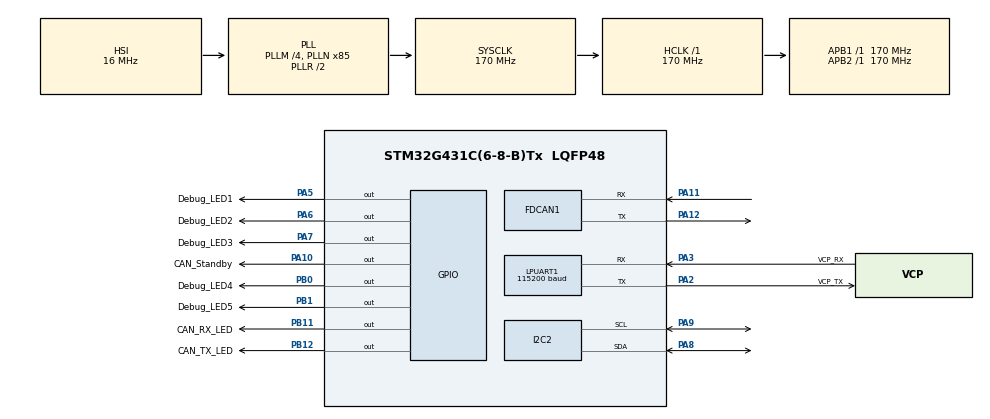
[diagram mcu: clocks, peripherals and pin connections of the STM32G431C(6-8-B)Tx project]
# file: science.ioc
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Dma.LPUART1_TX.0.Direction=DMA_MEMORY_TO_PERIPH
Dma.LPUART1_TX.0.EventEnable=DISABLE
Dma.LPUART1_TX.0.Instance=DMA2_Channel1
Dma.LPUART1_TX.0.MemDataAlignment=DMA_MDATAALIGN_BYTE
Dma.LPUART1_TX.0.MemInc=DMA_MINC_ENABLE
Dma.LPUART1_TX.0.Mode=DMA_NORMAL
Dma.LPUART1_TX.0.PeriphDataAlignment=DMA_PDATAALIGN_BYTE
Dma.LPUART1_TX.0.PeriphInc=DMA_PINC_DISABLE
Dma.LPUART1_TX.0.Polarity=HAL_DMAMUX_REQ_GEN_RISING
Dma.LPUART1_TX.0.Priority=DMA_PRIORITY_LOW
Dma.LPUART1_TX.0.RequestNumber=1
Dma.LPUART1_TX.0.SignalID=NONE
Dma.LPUART1_TX.0.SyncEnable=DISABLE
Dma.LPUART1_TX.0.SyncPolarity=HAL_DMAMUX_SYNC_NO_EVENT
Dma.LPUART1_TX.0.SyncRequestNumber=1
Dma.LPUART1_TX.0.SyncSignalID=NONE
Dma.Request0=LPUART1_TX
FDCAN1.AutoRetransmission=ENABLE
FDCAN1.CalculateBaudRateNominal=999999
FDCAN1.CalculateTimeBitNominal=1000
FDCAN1.CalculateTimeQuantumNominal=11.764705882352942
FDCAN1.ClockDivider=FDCAN_CLOCK_DIV2
FDCAN1.DataSyncJumpWidth=5
FDCAN1.DataTimeSeg1=11
FDCAN1.DataTimeSeg2=5
FDCAN1.ExtFiltersNbr=3
FDCAN1.FrameFormat=FDCAN_FRAME_FD_BRS
FDCAN1.NominalPrescaler=1
FDCAN1.NominalSyncJumpWidth=16
FDCAN1.NominalTimeSeg1=56
FDCAN1.NominalTimeSeg2=28
I2C2.Timing=0x40B285C2
LPUART1.BaudRate=115200
LPUART1.FIFOMode=UART_FIFOMODE_ENABLE
Mcu.Family=STM32G4
Mcu.Name=STM32G431C(6-8-B)Tx
Mcu.Package=LQFP48
NVIC.DMA2_Channel1_IRQn=true\:6\:0\:true\:false\:true\:false\:true\:true
NVIC.FDCAN1_IT0_IRQn=true\:0\:0\:false\:false\:true\:true\:true\:true
NVIC.FDCAN1_IT1_IRQn=true\:0\:0\:false\:false\:true\:true\:true\:true
NVIC.LPUART1_IRQn=true\:0\:0\:false\:false\:true\:true\:true\:true
NVIC.PriorityGroup=NVIC_PRIORITYGROUP_3
NVIC.TIM1_BRK_TIM15_IRQn=true\:0\:0\:true\:false\:true\:true\:true\:true
NVIC.TIM1_UP_TIM16_IRQn=true\:0\:0\:true\:false\:true\:true\:true\:true
NVIC.TIM2_IRQn=true\:3\:0\:true\:false\:true\:true\:true\:true
NVIC.TIM3_IRQn=true\:2\:0\:true\:false\:true\:true\:true\:true
NVIC.TIM6_DAC_IRQn=true\:4\:0\:true\:false\:true\:true\:true\:true
NVIC.TIM7_IRQn=true\:0\:0\:true\:false\:true\:true\:true\:true
PA10.GPIO_Label=CAN_Standby
PA10.Signal=GPIO_Output
PA11.Mode=FDCAN_Activate
PA11.Signal=FDCAN1_RX
PA12.Mode=FDCAN_Activate
PA12.Signal=FDCAN1_TX
PA13.GPIO_Label=SWDIO
PA13.Mode=Trace_Asynchronous_SW
PA13.Signal=SYS_JTMS-SWDIO
PA14.GPIO_Label=SWCLK
PA14.Mode=Trace_Asynchronous_SW
PA14.Signal=SYS_JTCK-SWCLK
PA2.GPIO_Label=VCP_TX
PA2.Mode=Asynchronous
PA2.Signal=LPUART1_TX
PA3.GPIO_Label=VCP_RX
PA3.Mode=Asynchronous
PA3.Signal=LPUART1_RX
PA5.GPIO_Label=Debug_LED1
PA5.Signal=GPIO_Output
PA6.GPIO_Label=Debug_LED2
PA6.Signal=GPIO_Output
PA7.GPIO_Label=Debug_LED3
PA7.Signal=GPIO_Output
PA8.Mode=I2C
PA8.Signal=I2C2_SDA
PA9.Mode=I2C
PA9.Signal=I2C2_SCL
PB0.GPIO_Label=Debug_LED4
PB0.Signal=GPIO_Output
PB1.GPIO_Label=Debug_LED5
PB1.Signal=GPIO_Output
PB11.GPIO_Label=CAN_RX_LED
PB11.Signal=GPIO_Output
PB12.GPIO_Label=CAN_TX_LED
PB12.Signal=GPIO_Output
PB3.GPIO_Label=SWO
PB3.Mode=Trace_Asynchronous_SW
PB3.Signal=SYS_JTDO-SWO
ProjectManager.HeapSize=0x200
ProjectManager.StackSize=0x400
ProjectManager.TargetToolchain=CMake
RCC.ADC12Freq_Value=170000000
RCC.AHBFreq_Value=170000000
RCC.APB1Freq_Value=170000000
RCC.APB1TimFreq_Value=170000000
RCC.APB2Freq_Value=170000000
RCC.APB2TimFreq_Value=170000000
RCC.CortexFreq_Value=170000000
RCC.EXTERNAL_CLOCK_VALUE=12288000
RCC.HCLKFreq_Value=170000000
RCC.HSE_VALUE=8000000
RCC.HSI48_VALUE=48000000
RCC.HSI_VALUE=16000000
RCC.LSE_VALUE=32768
RCC.PLLM=RCC_PLLM_DIV4
RCC.PLLN=85
RCC.SYSCLKFreq_VALUE=170000000
RCC.SYSCLKSource=RCC_SYSCLKSOURCE_PLLCLK
RCC.USBFreq_Value=170000000
RCC.VCOOutputFreq_Value=340000000
TIM15.PeriodNoDither=999
TIM15.Prescaler=16999
TIM16.PeriodNoDither=9999
TIM16.Prescaler=16999
TIM2.PeriodNoDither=3999
TIM2.Prescaler=16999
TIM3.PeriodNoDither=999
TIM3.Prescaler=16999
TIM6.PeriodNoDither=4999
TIM6.Prescaler=16999
TIM7.PeriodNoDither=499
TIM7.Prescaler=16999
VP_SYS_VS_DBSignals.Mode=DisableDeadBatterySignals
VP_TIM15_VS_ClockSourceINT.Mode=Internal
VP_TIM16_VS_ClockSourceINT.Mode=Enable_Timer
VP_TIM2_VS_ClockSourceINT.Mode=Internal
VP_TIM3_VS_ClockSourceINT.Mode=Internal
VP_TIM6_VS_ClockSourceINT.Mode=Enable_Timer
VP_TIM7_VS_ClockSourceINT.Mode=Enable_Timer
board=custom

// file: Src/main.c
/* USER CODE BEGIN Header */
/**
  ******************************************************************************
  * @file           : main.c
  * @brief          : Main program body
  ******************************************************************************
  * @attention
  *
  * Copyright (c) 2026 STMicroelectronics.
  * All rights reserved.
  *
  * This software is licensed under terms that can be found in the LICENSE file
  * in the root directory of this software component.
  * If no LICENSE file comes with this software, it is provided AS-IS.
  *
  ******************************************************************************
  */
/* USER CODE END Header */
#include "main.h"

FDCAN_HandleTypeDef hfdcan1;

I2C_HandleTypeDef hi2c2;

UART_HandleTypeDef hlpuart1;
DMA_HandleTypeDef hdma_lpuart1_tx;

TIM_HandleTypeDef htim2;
TIM_HandleTypeDef htim3;
TIM_HandleTypeDef htim6;
TIM_HandleTypeDef htim7;
TIM_HandleTypeDef htim15;
TIM_HandleTypeDef htim16;

void SystemClock_Config(void);
static void MX_GPIO_Init(void);
static void MX_DMA_Init(void);
static void MX_FDCAN1_Init(void);
static void MX_TIM2_Init(void);
static void MX_TIM3_Init(void);
static void MX_LPUART1_UART_Init(void);
static void MX_TIM6_Init(void);
static void MX_TIM15_Init(void);
static void MX_TIM16_Init(void);
static void MX_TIM7_Init(void);
static void MX_I2C2_Init(void);

int main(void)
{

  /* MCU Configuration--------------------------------------------------------*/

  /* Reset of all peripherals, Initializes the Flash interface and the Systick. */
  HAL_Init();

  /* Configure the system clock */
  SystemClock_Config();

  /* Initialize all configured peripherals */
  MX_GPIO_Init();
  MX_DMA_Init();
  MX_FDCAN1_Init();
  MX_TIM2_Init();
  MX_TIM3_Init();
  MX_LPUART1_UART_Init();
  MX_TIM6_Init();
  MX_TIM15_Init();
  MX_TIM16_Init();
  MX_TIM7_Init();
  MX_I2C2_Init();

  /* Infinite loop */
  /* USER CODE BEGIN WHILE */
  PostInit();
  while (1)
  {
    /* USER CODE END WHILE */

  }
}

void SystemClock_Config(void)
{
  RCC_OscInitTypeDef RCC_OscInitStruct = {0};
  RCC_ClkInitTypeDef RCC_ClkInitStruct = {0};

  /** Configure the main internal regulator output voltage
  */
  HAL_PWREx_ControlVoltageScaling(PWR_REGULATOR_VOLTAGE_SCALE1_BOOST);

  /** Initializes the RCC Oscillators according to the specified parameters
  * in the RCC_OscInitTypeDef structure.
  */
  RCC_OscInitStruct.OscillatorType = RCC_OSCILLATORTYPE_HSI;
  RCC_OscInitStruct.HSIState = RCC_HSI_ON;
  RCC_OscInitStruct.HSICalibrationValue = RCC_HSICALIBRATION_DEFAULT;
  RCC_OscInitStruct.PLL.PLLState = RCC_PLL_ON;
  RCC_OscInitStruct.PLL.PLLSource = RCC_PLLSOURCE_HSI;
  RCC_OscInitStruct.PLL.PLLM = RCC_PLLM_DIV4;
  RCC_OscInitStruct.PLL.PLLN = 85;
  RCC_OscInitStruct.PLL.PLLP = RCC_PLLP_DIV2;
  RCC_OscInitStruct.PLL.PLLQ = RCC_PLLQ_DIV2;
  RCC_OscInitStruct.PLL.PLLR = RCC_PLLR_DIV2;
  if (HAL_RCC_OscConfig(&RCC_OscInitStruct) != HAL_OK)
  {
    Error_Handler();
  }

  /** Initializes the CPU, AHB and APB buses clocks
  */
  RCC_ClkInitStruct.ClockType = RCC_CLOCKTYPE_HCLK|RCC_CLOCKTYPE_SYSCLK
                              |RCC_CLOCKTYPE_PCLK1|RCC_CLOCKTYPE_PCLK2;
  RCC_ClkInitStruct.SYSCLKSource = RCC_SYSCLKSOURCE_PLLCLK;
  RCC_ClkInitStruct.AHBCLKDivider = RCC_SYSCLK_DIV1;
  RCC_ClkInitStruct.APB1CLKDivider = RCC_HCLK_DIV1;
  RCC_ClkInitStruct.APB2CLKDivider = RCC_HCLK_DIV1;

  if (HAL_RCC_ClockConfig(&RCC_ClkInitStruct, FLASH_LATENCY_4) != HAL_OK)
  {
    Error_Handler();
  }
}

static void MX_FDCAN1_Init(void)
{

  hfdcan1.Instance = FDCAN1;
  hfdcan1.Init.ClockDivider = FDCAN_CLOCK_DIV2;
  hfdcan1.Init.FrameFormat = FDCAN_FRAME_FD_BRS;
  hfdcan1.Init.Mode = FDCAN_MODE_NORMAL;
  hfdcan1.Init.AutoRetransmission = ENABLE;
  hfdcan1.Init.TransmitPause = DISABLE;
  hfdcan1.Init.ProtocolException = DISABLE;
  hfdcan1.Init.NominalPrescaler = 1;
  hfdcan1.Init.NominalSyncJumpWidth = 16;
  hfdcan1.Init.NominalTimeSeg1 = 56;
  hfdcan1.Init.NominalTimeSeg2 = 28;
  hfdcan1.Init.DataPrescaler = 1;
  hfdcan1.Init.DataSyncJumpWidth = 5;
  hfdcan1.Init.DataTimeSeg1 = 11;
  hfdcan1.Init.DataTimeSeg2 = 5;
  hfdcan1.Init.StdFiltersNbr = 0;
  hfdcan1.Init.ExtFiltersNbr = 3;
  hfdcan1.Init.TxFifoQueueMode = FDCAN_TX_FIFO_OPERATION;
  if (HAL_FDCAN_Init(&hfdcan1) != HAL_OK)
  {
    Error_Handler();
  }

}

static void MX_I2C2_Init(void)
{

  hi2c2.Instance = I2C2;
  hi2c2.Init.Timing = 0x40B285C2;
  hi2c2.Init.OwnAddress1 = 0;
  hi2c2.Init.AddressingMode = I2C_ADDRESSINGMODE_7BIT;
  hi2c2.Init.DualAddressMode = I2C_DUALADDRESS_DISABLE;
  hi2c2.Init.OwnAddress2 = 0;
  hi2c2.Init.OwnAddress2Masks = I2C_OA2_NOMASK;
  hi2c2.Init.GeneralCallMode = I2C_GENERALCALL_DISABLE;
  hi2c2.Init.NoStretchMode = I2C_NOSTRETCH_DISABLE;
  if (HAL_I2C_Init(&hi2c2) != HAL_OK)
  {
    Error_Handler();
  }

  /** Configure Analogue filter
  */
  if (HAL_I2CEx_ConfigAnalogFilter(&hi2c2, I2C_ANALOGFILTER_ENABLE) != HAL_OK)
  {
    Error_Handler();
  }

  /** Configure Digital filter
  */
  if (HAL_I2CEx_ConfigDigitalFilter(&hi2c2, 0) != HAL_OK)
  {
    Error_Handler();
  }

}

static void MX_LPUART1_UART_Init(void)
{

  hlpuart1.Instance = LPUART1;
  hlpuart1.Init.BaudRate = 115200;
  hlpuart1.Init.WordLength = UART_WORDLENGTH_8B;
  hlpuart1.Init.StopBits = UART_STOPBITS_1;
  hlpuart1.Init.Parity = UART_PARITY_NONE;
  hlpuart1.Init.Mode = UART_MODE_TX_RX;
  hlpuart1.Init.HwFlowCtl = UART_HWCONTROL_NONE;
  hlpuart1.Init.OneBitSampling = UART_ONE_BIT_SAMPLE_DISABLE;
  hlpuart1.Init.ClockPrescaler = UART_PRESCALER_DIV1;
  hlpuart1.AdvancedInit.AdvFeatureInit = UART_ADVFEATURE_NO_INIT;
  if (HAL_UART_Init(&hlpuart1) != HAL_OK)
  {
    Error_Handler();
  }
  if (HAL_UARTEx_SetTxFifoThreshold(&hlpuart1, UART_TXFIFO_THRESHOLD_1_8) != HAL_OK)
  {
    Error_Handler();
  }
  if (HAL_UARTEx_SetRxFifoThreshold(&hlpuart1, UART_RXFIFO_THRESHOLD_1_8) != HAL_OK)
  {
    Error_Handler();
  }
  if (HAL_UARTEx_EnableFifoMode(&hlpuart1) != HAL_OK)
  {
    Error_Handler();
  }

}

static void MX_TIM2_Init(void)
{

  TIM_ClockConfigTypeDef sClockSourceConfig = {0};
  TIM_MasterConfigTypeDef sMasterConfig = {0};

  htim2.Instance = TIM2;
  htim2.Init.Prescaler = 16999;
  htim2.Init.CounterMode = TIM_COUNTERMODE_UP;
  htim2.Init.Period = 3999;
  htim2.Init.ClockDivision = TIM_CLOCKDIVISION_DIV1;
  htim2.Init.AutoReloadPreload = TIM_AUTORELOAD_PRELOAD_DISABLE;
  if (HAL_TIM_Base_Init(&htim2) != HAL_OK)
  {
    Error_Handler();
  }
  sClockSourceConfig.ClockSource = TIM_CLOCKSOURCE_INTERNAL;
  if (HAL_TIM_ConfigClockSource(&htim2, &sClockSourceConfig) != HAL_OK)
  {
    Error_Handler();
  }
  sMasterConfig.MasterOutputTrigger = TIM_TRGO_RESET;
  sMasterConfig.MasterSlaveMode = TIM_MASTERSLAVEMODE_DISABLE;
  if (HAL_TIMEx_MasterConfigSynchronization(&htim2, &sMasterConfig) != HAL_OK)
  {
    Error_Handler();
  }

}

static void MX_TIM3_Init(void)
{

  TIM_ClockConfigTypeDef sClockSourceConfig = {0};
  TIM_MasterConfigTypeDef sMasterConfig = {0};

  htim3.Instance = TIM3;
  htim3.Init.Prescaler = 16999;
  htim3.Init.CounterMode = TIM_COUNTERMODE_UP;
  htim3.Init.Period = 999;
  htim3.Init.ClockDivision = TIM_CLOCKDIVISION_DIV1;
  htim3.Init.AutoReloadPreload = TIM_AUTORELOAD_PRELOAD_DISABLE;
  if (HAL_TIM_Base_Init(&htim3) != HAL_OK)
  {
    Error_Handler();
  }
  sClockSourceConfig.ClockSource = TIM_CLOCKSOURCE_INTERNAL;
  if (HAL_TIM_ConfigClockSource(&htim3, &sClockSourceConfig) != HAL_OK)
  {
    Error_Handler();
  }
  sMasterConfig.MasterOutputTrigger = TIM_TRGO_RESET;
  sMasterConfig.MasterSlaveMode = TIM_MASTERSLAVEMODE_DISABLE;
  if (HAL_TIMEx_MasterConfigSynchronization(&htim3, &sMasterConfig) != HAL_OK)
  {
    Error_Handler();
  }

}

static void MX_TIM6_Init(void)
{

  TIM_MasterConfigTypeDef sMasterConfig = {0};

  htim6.Instance = TIM6;
  htim6.Init.Prescaler = 16999;
  htim6.Init.CounterMode = TIM_COUNTERMODE_UP;
  htim6.Init.Period = 4999;
  htim6.Init.AutoReloadPreload = TIM_AUTORELOAD_PRELOAD_DISABLE;
  if (HAL_TIM_Base_Init(&htim6) != HAL_OK)
  {
    Error_Handler();
  }
  sMasterConfig.MasterOutputTrigger = TIM_TRGO_RESET;
  sMasterConfig.MasterSlaveMode = TIM_MASTERSLAVEMODE_DISABLE;
  if (HAL_TIMEx_MasterConfigSynchronization(&htim6, &sMasterConfig) != HAL_OK)
  {
    Error_Handler();
  }

}

static void MX_TIM7_Init(void)
{

  TIM_MasterConfigTypeDef sMasterConfig = {0};

  htim7.Instance = TIM7;
  htim7.Init.Prescaler = 16999;
  htim7.Init.CounterMode = TIM_COUNTERMODE_UP;
  htim7.Init.Period = 499;
  htim7.Init.AutoReloadPreload = TIM_AUTORELOAD_PRELOAD_DISABLE;
  if (HAL_TIM_Base_Init(&htim7) != HAL_OK)
  {
    Error_Handler();
  }
  sMasterConfig.MasterOutputTrigger = TIM_TRGO_RESET;
  sMasterConfig.MasterSlaveMode = TIM_MASTERSLAVEMODE_DISABLE;
  if (HAL_TIMEx_MasterConfigSynchronization(&htim7, &sMasterConfig) != HAL_OK)
  {
    Error_Handler();
  }

}

static void MX_TIM15_Init(void)
{

  TIM_ClockConfigTypeDef sClockSourceConfig = {0};
  TIM_MasterConfigTypeDef sMasterConfig = {0};

  htim15.Instance = TIM15;
  htim15.Init.Prescaler = 16999;
  htim15.Init.CounterMode = TIM_COUNTERMODE_UP;
  htim15.Init.Period = 999;
  htim15.Init.ClockDivision = TIM_CLOCKDIVISION_DIV1;
  htim15.Init.RepetitionCounter = 0;
  htim15.Init.AutoReloadPreload = TIM_AUTORELOAD_PRELOAD_DISABLE;
  if (HAL_TIM_Base_Init(&htim15) != HAL_OK)
  {
    Error_Handler();
  }
  sClockSourceConfig.ClockSource = TIM_CLOCKSOURCE_INTERNAL;
  if (HAL_TIM_ConfigClockSource(&htim15, &sClockSourceConfig) != HAL_OK)
  {
    Error_Handler();
  }
  sMasterConfig.MasterOutputTrigger = TIM_TRGO_RESET;
  sMasterConfig.MasterSlaveMode = TIM_MASTERSLAVEMODE_DISABLE;
  if (HAL_TIMEx_MasterConfigSynchronization(&htim15, &sMasterConfig) != HAL_OK)
  {
    Error_Handler();
  }

}

static void MX_TIM16_Init(void)
{

  htim16.Instance = TIM16;
  htim16.Init.Prescaler = 16999;
  htim16.Init.CounterMode = TIM_COUNTERMODE_UP;
  htim16.Init.Period = 9999;
  htim16.Init.ClockDivision = TIM_CLOCKDIVISION_DIV1;
  htim16.Init.RepetitionCounter = 0;
  htim16.Init.AutoReloadPreload = TIM_AUTORELOAD_PRELOAD_DISABLE;
  if (HAL_TIM_Base_Init(&htim16) != HAL_OK)
  {
    Error_Handler();
  }

}

static void MX_DMA_Init(void)
{

  /* DMA controller clock enable */
  __HAL_RCC_DMAMUX1_CLK_ENABLE();
  __HAL_RCC_DMA2_CLK_ENABLE();

  /* DMA interrupt init */
  /* DMA2_Channel1_IRQn interrupt configuration */
  HAL_NVIC_SetPriority(DMA2_Channel1_IRQn, 6, 0);
  HAL_NVIC_EnableIRQ(DMA2_Channel1_IRQn);

}

static void MX_GPIO_Init(void)
{
  GPIO_InitTypeDef GPIO_InitStruct = {0};

  /* GPIO Ports Clock Enable */
  __HAL_RCC_GPIOA_CLK_ENABLE();
  __HAL_RCC_GPIOB_CLK_ENABLE();

  /*Configure GPIO pin Output Level */
  HAL_GPIO_WritePin(GPIOA, Debug_LED1_Pin|Debug_LED2_Pin|Debug_LED3_Pin|CAN_Standby_Pin, GPIO_PIN_RESET);

  /*Configure GPIO pin Output Level */
  HAL_GPIO_WritePin(GPIOB, Debug_LED4_Pin|Debug_LED5_Pin|CAN_RX_LED_Pin|CAN_TX_LED_Pin, GPIO_PIN_RESET);

  /*Configure GPIO pins : Debug_LED1_Pin Debug_LED2_Pin Debug_LED3_Pin CAN_Standby_Pin */
  GPIO_InitStruct.Pin = Debug_LED1_Pin|Debug_LED2_Pin|Debug_LED3_Pin|CAN_Standby_Pin;
  GPIO_InitStruct.Mode = GPIO_MODE_OUTPUT_PP;
  GPIO_InitStruct.Pull = GPIO_NOPULL;
  GPIO_InitStruct.Speed = GPIO_SPEED_FREQ_LOW;
  HAL_GPIO_Init(GPIOA, &GPIO_InitStruct);

  /*Configure GPIO pins : Debug_LED4_Pin Debug_LED5_Pin CAN_RX_LED_Pin CAN_TX_LED_Pin */
  GPIO_InitStruct.Pin = Debug_LED4_Pin|Debug_LED5_Pin|CAN_RX_LED_Pin|CAN_TX_LED_Pin;
  GPIO_InitStruct.Mode = GPIO_MODE_OUTPUT_PP;
  GPIO_InitStruct.Pull = GPIO_NOPULL;
  GPIO_InitStruct.Speed = GPIO_SPEED_FREQ_LOW;
  HAL_GPIO_Init(GPIOB, &GPIO_InitStruct);

}

void Error_Handler(void)
{
  __disable_irq();
  while (1)
  {
  }
}
